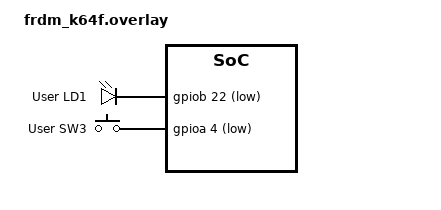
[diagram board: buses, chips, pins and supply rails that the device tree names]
/{
  leds{
    compatible = "gpio-leds";
    myled: myled{
      gpios = <&gpiob 22 GPIO_ACTIVE_LOW>;
			label = "User LD1";
    };
  };

  buttons{
    compatible = "gpio-keys";
		mybutton: mybutton {
			label = "User SW3";
			gpios = <&gpioa 4 GPIO_ACTIVE_LOW>;
		};
  };
};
